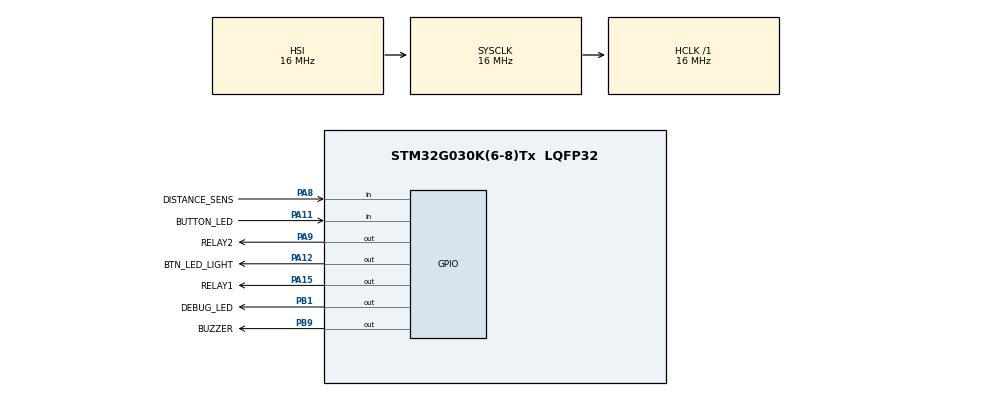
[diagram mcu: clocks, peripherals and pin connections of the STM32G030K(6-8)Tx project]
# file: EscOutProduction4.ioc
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IWDG.Prescaler=IWDG_PRESCALER_16
Mcu.Family=STM32G0
Mcu.Name=STM32G030K(6-8)Tx
Mcu.Package=LQFP32
NVIC.TIM1_BRK_UP_TRG_COM_IRQn=true\:0\:0\:false\:false\:true\:true\:true\:true
PA11\ [PA9].GPIO_Label=BUTTON_LED
PA11\ [PA9].Signal=GPIO_Input
PA12\ [PA10].GPIO_Label=BTN_LED_LIGHT
PA12\ [PA10].Signal=GPIO_Output
PA15.GPIO_Label=RELAY1
PA15.Signal=GPIO_Output
PA8.GPIO_Label=DISTANCE_SENS
PA8.Signal=GPIO_Input
PA9.GPIO_Label=RELAY2
PA9.PinState=GPIO_PIN_SET
PA9.Signal=GPIO_Output
PB1.GPIO_Label=DEBUG_LED
PB1.Signal=GPIO_Output
PB9.GPIO_FM9=SYSCFG_FASTMODEPLUS_PB9
PB9.GPIO_Label=BUZZER
PB9.PinState=GPIO_PIN_SET
PB9.Signal=GPIO_Output
ProjectManager.HeapSize=0x200
ProjectManager.StackSize=0x400
ProjectManager.TargetToolchain=STM32CubeIDE
RCC.AHBFreq_Value=16000000
RCC.CortexFreq_Value=16000000
RCC.EXTERNAL_CLOCK_VALUE=12288000
RCC.HCLKFreq_Value=16000000
RCC.HSE_VALUE=8000000
RCC.HSI_VALUE=16000000
RCC.LSE_VALUE=32768
RCC.SYSCLKFreq_VALUE=16000000
RCC.VCOOutputFreq_Value=128000000
TIM1.Period=95
TIM1.Prescaler=40
VP_IWDG_VS_IWDG.Mode=IWDG_Activate
VP_TIM1_VS_ClockSourceINT.Mode=Internal
board=custom

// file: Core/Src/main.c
/* USER CODE BEGIN Header */
/**
  ******************************************************************************
  * @file           : main.c
  * @brief          : Main program body
  ******************************************************************************
  * @attention
  *
  * Copyright (c) 2023 STMicroelectronics.
  * All rights reserved.
  *
  * This software is licensed under terms that can be found in the LICENSE file
  * in the root directory of this software component.
  * If no LICENSE file comes with this software, it is provided AS-IS.
  *
  ******************************************************************************
  */
/* USER CODE END Header */
#include "main.h"
#include "iwdg.h"
#include "tim.h"
#include "gpio.h"

/* USER CODE BEGIN Includes */
#include "app/toy_pulling.h"
#include "app/watchdog.h"
/* USER CODE END Includes */

void SystemClock_Config(void);
/* USER CODE BEGIN PFP */
void DEBUG_LED_Blink(uint8_t blink_times);
/* USER CODE END PFP */

int main(void)
{

  /* MCU Configuration--------------------------------------------------------*/

  /* Reset of all peripherals, Initializes the Flash interface and the Systick. */
  HAL_Init();

  /* Configure the system clock */
  SystemClock_Config();

  /* Initialize all configured peripherals */
  MX_GPIO_Init();
  MX_IWDG_Init();
  MX_TIM1_Init();
  /* USER CODE BEGIN 2 */
  __HAL_DBGMCU_FREEZE_IWDG();
  TOY_PULLING_Init();
  DEBUG_LED_Blink(1);
  /* USER CODE END 2 */

  /* Infinite loop */
  /* USER CODE BEGIN WHILE */
  while (1)
  {
	  TOY_PULLING_Process();
	  WATCHDOG_Refresh();
    /* USER CODE END WHILE */

  }
}

void SystemClock_Config(void)
{
  RCC_OscInitTypeDef RCC_OscInitStruct = {0};
  RCC_ClkInitTypeDef RCC_ClkInitStruct = {0};

  /** Configure the main internal regulator output voltage
  */
  HAL_PWREx_ControlVoltageScaling(PWR_REGULATOR_VOLTAGE_SCALE1);

  /** Initializes the RCC Oscillators according to the specified parameters
  * in the RCC_OscInitTypeDef structure.
  */
  RCC_OscInitStruct.OscillatorType = RCC_OSCILLATORTYPE_HSI|RCC_OSCILLATORTYPE_LSI;
  RCC_OscInitStruct.HSIState = RCC_HSI_ON;
  RCC_OscInitStruct.HSIDiv = RCC_HSI_DIV1;
  RCC_OscInitStruct.HSICalibrationValue = RCC_HSICALIBRATION_DEFAULT;
  RCC_OscInitStruct.LSIState = RCC_LSI_ON;
  RCC_OscInitStruct.PLL.PLLState = RCC_PLL_NONE;
  if (HAL_RCC_OscConfig(&RCC_OscInitStruct) != HAL_OK)
  {
    Error_Handler();
  }

  /** Initializes the CPU, AHB and APB buses clocks
  */
  RCC_ClkInitStruct.ClockType = RCC_CLOCKTYPE_HCLK|RCC_CLOCKTYPE_SYSCLK
                              |RCC_CLOCKTYPE_PCLK1;
  RCC_ClkInitStruct.SYSCLKSource = RCC_SYSCLKSOURCE_HSI;
  RCC_ClkInitStruct.AHBCLKDivider = RCC_SYSCLK_DIV1;
  RCC_ClkInitStruct.APB1CLKDivider = RCC_HCLK_DIV1;

  if (HAL_RCC_ClockConfig(&RCC_ClkInitStruct, FLASH_LATENCY_0) != HAL_OK)
  {
    Error_Handler();
  }
}

/* USER CODE BEGIN 4 */
void DEBUG_LED_Blink(uint8_t blink_times)
{
	for(uint8_t i=0; i<blink_times*2; i++)
	{
		HAL_GPIO_TogglePin(DEBUG_LED_GPIO_Port, DEBUG_LED_Pin);
		HAL_Delay(250);
		WATCHDOG_Refresh();
	}
}
/* USER CODE END 4 */

void Error_Handler(void)
{
  __disable_irq();
  while (1)
  {
  }
}
